# ADuCM320 register map
Vendor: Analog Devices Inc.; Series: ARMCM3; File version: 1.1
CPU: CM3 r2p1, little endian, no MPU, no FPU, 3 interrupt priority bits
Registers are 16-bit, read-write, no defined reset value unless marked. A register's access mark holds for its fields unless they carry their own. Offsets are from the block's base; [hi:lo] are bit positions; {n}, {i} and the like mark numbered series.

## MDIO — MDIO Interface
Base 0x40005C00
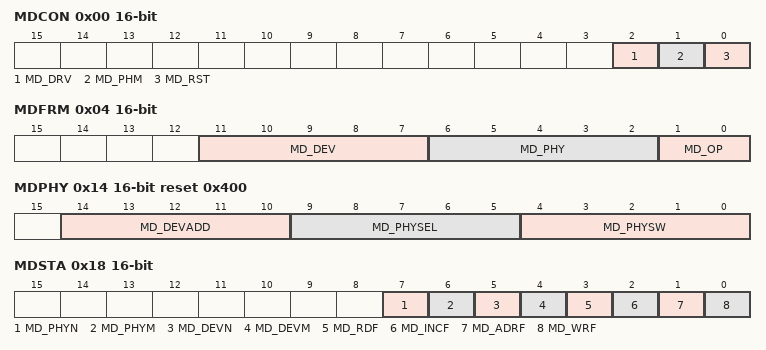
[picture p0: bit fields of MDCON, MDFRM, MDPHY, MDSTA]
0x00 MDCON — MDIO block control
  [2] MD_DRV
    0=MD_DRV_OD (MDIO drive open drain.); 1=MD_DRV_PP (MDIO drive push-pull.)
  [1] MD_PHM range 0x00000000..0x00000001
  [0] MD_RST wo range 0x00000000..0x00000001
0x04 MDFRM ro — MDIO received frame control information
  [11:7] MD_DEV range 0x00000000..0x0000001F
  [6:2] MD_PHY range 0x00000000..0x0000001F
  [1:0] MD_OP
    0=MD_OP_ADF (Address frame.); 1=MD_OP_WRF (Write frame.); 2=MD_OP_INCF (PostReadIncAdd frame.); 3=MD_OP_RDF (Read frame.)
0x08 MDRXD ro — MDIO received data
  [15:0] MD_RXD range 0x00000000..0x0000FFFF
0x0C MDADR ro — MDIO received address
  [15:0] MD_ADR range 0x00000000..0x0000FFFF
0x10 MDTXD — MDIO data for transmission
  [15:0] MD_TXD range 0x00000000..0x0000FFFF
0x14 MDPHY reset 0x400 (reset mask 0x0) — MDIO PHYADDR software values and selection and DEVADD
  [14:10] MD_DEVADD range 0x00000000..0x0000001F, [9:5] MD_PHYSEL range 0x00000000..0x0000001F, [4:0] MD_PHYSW range 0x00000000..0x0000001F
0x18 MDSTA — MDIO progress signaling through frame
  [7] MD_PHYN ro range 0x00000000..0x00000001, [6] MD_PHYM ro range 0x00000000..0x00000001, [5] MD_DEVN ro range 0x00000000..0x00000001, [4] MD_DEVM ro range 0x00000000..0x00000001, [3] MD_RDF ro range 0x00000000..0x00000001, [2] MD_INCF ro range 0x00000000..0x00000001, [1] MD_ADRF ro range 0x00000000..0x00000001, [0] MD_WRF ro range 0x00000000..0x00000001
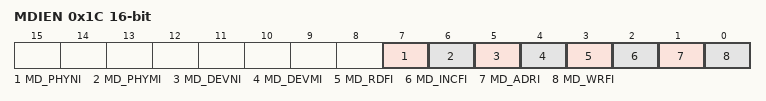
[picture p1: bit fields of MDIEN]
0x1C MDIEN — MDIO interrupt enables
  [7] MD_PHYNI range 0x00000000..0x00000001, [6] MD_PHYMI range 0x00000000..0x00000001, [5] MD_DEVNI range 0x00000000..0x00000001, [4] MD_DEVMI range 0x00000000..0x00000001, [3] MD_RDFI range 0x00000000..0x00000001, [2] MD_INCFI range 0x00000000..0x00000001, [1] MD_ADRI range 0x00000000..0x00000001, [0] MD_WRFI range 0x00000000..0x00000001
0x20 MDPIN — MDIO read PHYADDR pins
  [4:0] MD_PIN ro range 0x00000000..0x0000001F

## PLA — Programmable Logic Array
Base 0x40005800
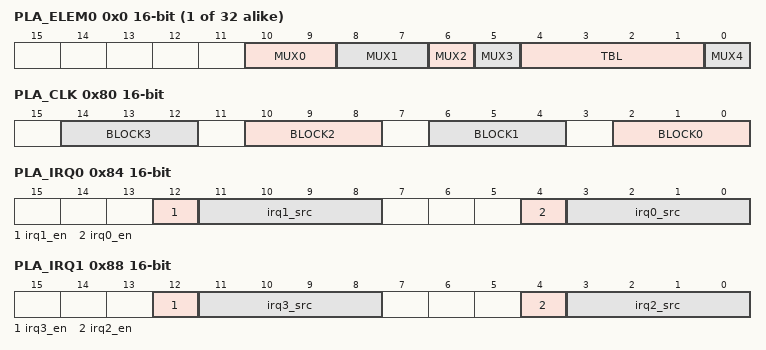
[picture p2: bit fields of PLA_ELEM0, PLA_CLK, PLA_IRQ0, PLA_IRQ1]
{0x0+4i} PLA_ELEM{i} (i=0..31) — ELEMx Configuration Register
  [10:9] MUX0 — Even element feedback selection (in respective block)
    0=ELEM0 (Feedback from Element 0 (all except Element 0) / Input from other block (Element 0 only)); 1=ELEM2 (Feedback from Element 2); 2=ELEM4 (Feedback from Element 4); 3=ELEM6 (Feedback from Element 6)
  [8:7] MUX1 — Odd element feedback selection (in respective block)
    0=ELEM1 (Feedback from Element 1); 1=ELEM3 (Feedback from Element 3); 2=ELEM5 (Feedback from Element 5); 3=ELEM7 (Feedback from Element 7)
  [6] MUX2 — Select between correspondng bit from PLA_DINx register or even feedback mux
    0=MMR (PLA_DINx input); 1=EVEN (Even feedback mux)
  [5] MUX3 — Select between GPIO Bus input or odd feedback input (for Elements 16-31 odd feedback is always selected)
    0=ODD (odd feedback mux); 1=GPIO (input)
  [4:1] TBL — bit 4,3,2,1 configures output for {mux2_out, mux3_out} = 11,10,01,00 respectively
    0=LOW (0.); 1=NOR; 2=BANDNOTA; 3=NOTA; 4=AANDNOTB; 5=NOTB; 6=EXOR; 7=NAND; 8=AND; 9=EXNOR; 10=B; 11=BORNOTA; 12=A; 13=AORNOTB; 14=OR; 15=HIGH (1.)
  [0] MUX4 — Select or bypass flip-flop output
    0=FF (output); 1=BYPASS (Bypass output)
0x80 PLA_CLK — PLA Clock Select
  [all] fields
    0=P03 (GPIO clock on P0.3); 1=P11 (GPIO clock on P1.1); 2=P20 (GPIO clock on P2.0); 3=HCLK; 4=MOSC ((16 MHz)); 5=T0 (Timer 0); 6=T2 (Timer 2); 7=KOSC ((32 kHz))
  [4n+2:4n] BLOCK{n} (n=0..3) — Clock select for Block {n}
0x84 PLA_IRQ0 — Interrupt Register for Block 0 and 1
  [12] irq1_en — IRQ1 enable
    0=DIS (disable IRQ1 interrupt); 1=EN (enable IRQ1 interrupt)
  [11:8] irq1_src range 0x00000000..0x0000000F — IRQ1 source select (Elements 0-15). 4-bit value corresponds to element number (e.g. 1011 selects Element 11).
  [4] irq0_en — IRQ0 enable
    0=DIS (disable IRQ0 interrupt); 1=EN (enable IRQ0 interrupt)
  [3:0] irq0_src range 0x00000000..0x0000000F — IRQ0 source select (Elements 0-15). 4-bit value corresponds to element number (e.g. 1011 selects Element 11).
0x88 PLA_IRQ1 — Interrupt Register for Block 2 and 3
  [12] irq3_en — IRQ3 enable
    0=DIS (disable IRQ3 interrupt); 1=EN (enable IRQ3 interrupt)
  [11:8] irq3_src range 0x00000000..0x0000000F — IRQ3 source select (Elements 16-31) Element number corresponds to 4-bit value + 16 (e.g. 1011 selects Element 27).
  [4] irq2_en — IRQ2 enable
    0=DIS (disable IRQ2 interrupt); 1=EN (enable IRQ2 interrupt)
  [3:0] irq2_src range 0x00000000..0x0000000F — IRQ2 source select (Elements 16-31). Element number corresponds to 4-bit value + 16 (e.g. 1011 selects Element 27).
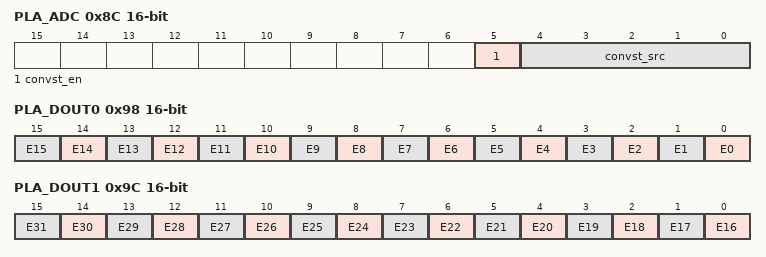
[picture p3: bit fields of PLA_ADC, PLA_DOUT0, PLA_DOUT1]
0x8C PLA_ADC — ADC Configuration Register
  [5] convst_en range 0x00000000..0x00000001 — Bit to enable ADC start convert from PLA
  [4:0] convst_src range 0x00000000..0x0000001F — Element for ADC start convert source. The binary value corresponds to the element number. For example Element 23 is 10111
0x90 PLA_DIN0 — AMBA Bus Data Input for Block 0 and 1
  [15:0] DIN range 0x00000000..0x0000FFFF
0x98 PLA_DOUT0 ro — AMBA Bus Data Output for Block 0 and 1
  [n] E{n} range 0x00000000..0x00000001 (n=0..15) — Output bit from Element {n}
0x9C PLA_DOUT1 ro — AMBA Bus Data Output for Block 2 and 3
  [n-16] E{n} range 0x00000000..0x00000001 (n=16..31) — Output bit from Element {n}
0xA0 PLA_LCK — Write lock Register. Can only be set once every reset
  [0] LOCK — Set to disable writing to registers
    0=DIS (Writing to registers allowed); 1=EN (Writing to registers disabled)
